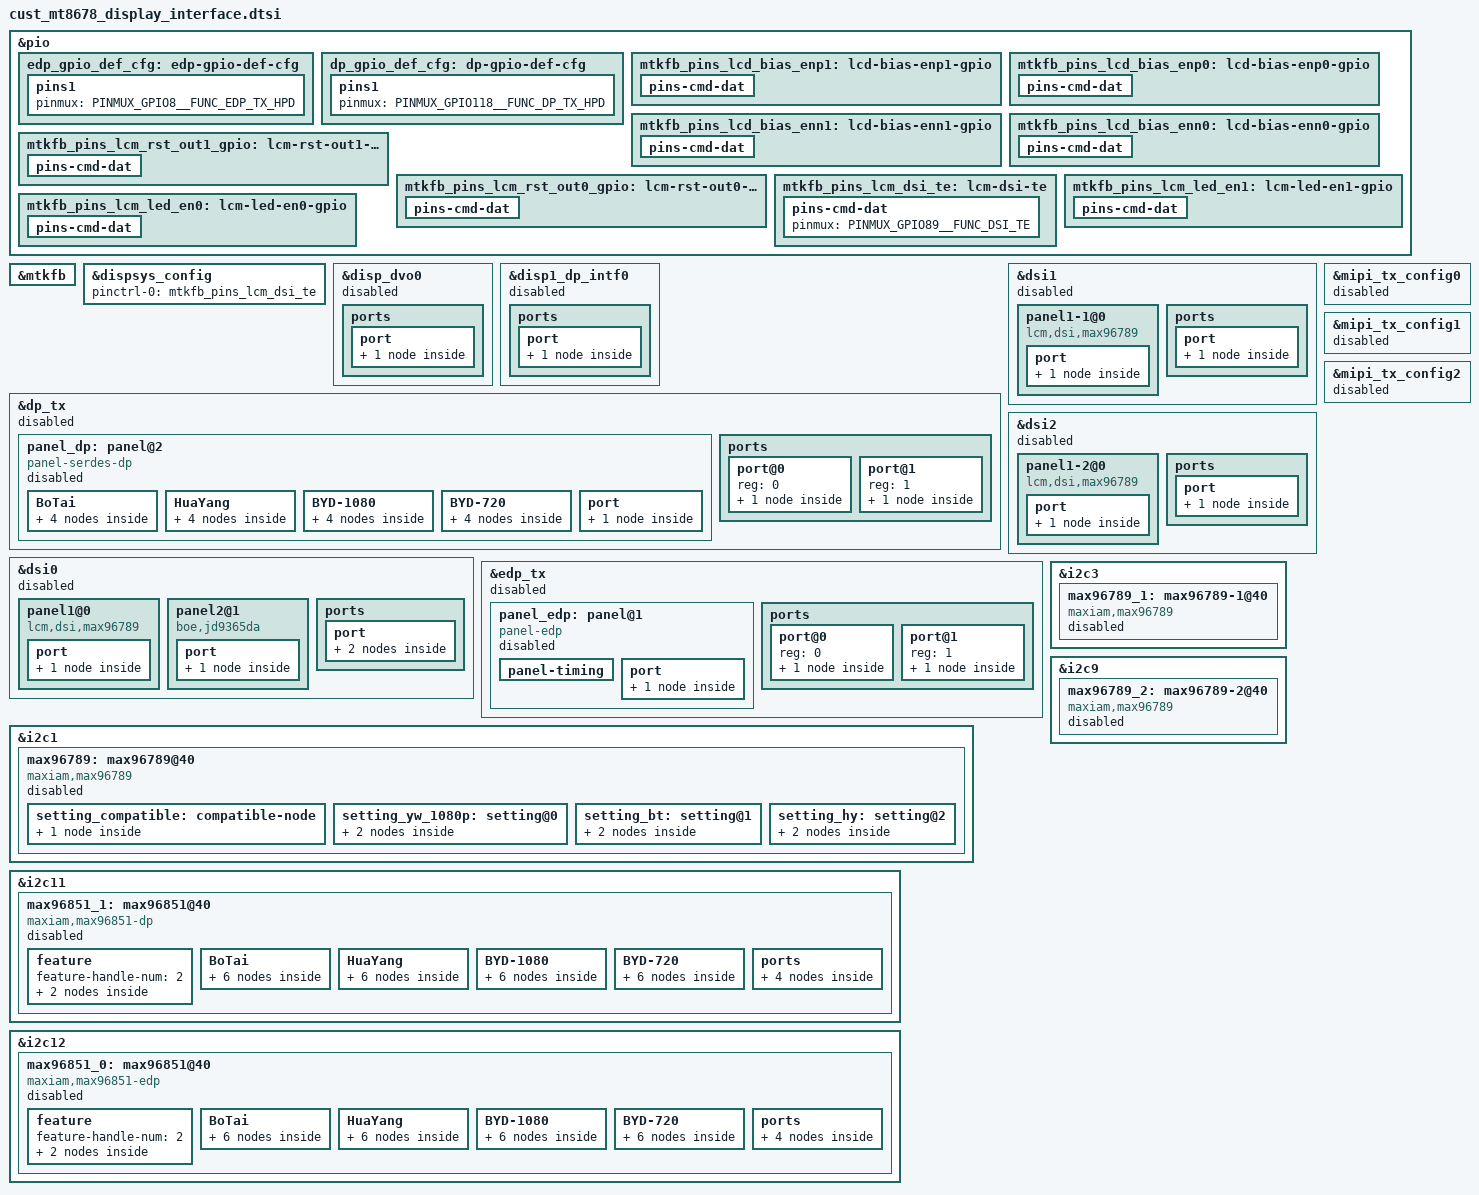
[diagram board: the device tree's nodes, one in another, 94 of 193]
// SPDX-License-Identifier: (GPL-2.0 OR MIT)
/*
 * Copyright (C) 2022 MediaTek Inc.
 */

&pio {
	edp_gpio_def_cfg: edp-gpio-def-cfg{
		pins1 {
			pinmux = <PINMUX_GPIO8__FUNC_EDP_TX_HPD>;
		};
	};

	dp_gpio_def_cfg: dp-gpio-def-cfg {
		pins1 {
			pinmux = <PINMUX_GPIO118__FUNC_DP_TX_HPD>;
		};
	};

	mtkfb_pins_lcd_bias_enp1: lcd-bias-enp1-gpio {
		pins-cmd-dat {
			pinmux = <PINMUX_GPIO103__FUNC_GPIO103>;
			slew-rate = <1>;
			output-high;
		};
	};

	mtkfb_pins_lcd_bias_enp0: lcd-bias-enp0-gpio {
		pins-cmd-dat {
			pinmux = <PINMUX_GPIO103__FUNC_GPIO103>;
			slew-rate = <1>;
			output-low;
		};
	};

	mtkfb_pins_lcd_bias_enn1: lcd-bias-enn1-gpio {
		pins-cmd-dat {
			pinmux = <PINMUX_GPIO103__FUNC_GPIO103>;
			slew-rate = <1>;
			output-high;
		};
	};

	mtkfb_pins_lcd_bias_enn0: lcd-bias-enn0-gpio {
		pins-cmd-dat {
			pinmux = <PINMUX_GPIO103__FUNC_GPIO103>;
			slew-rate = <1>;
			output-low;
		};
	};

	mtkfb_pins_lcm_rst_out1_gpio: lcm-rst-out1-gpio {
		pins-cmd-dat {
			pinmux = <PINMUX_GPIO90__FUNC_GPIO90>;
			slew-rate = <1>;
			output-high;
		};
	};

	mtkfb_pins_lcm_rst_out0_gpio: lcm-rst-out0-gpio {
		pins-cmd-dat {
			pinmux = <PINMUX_GPIO90__FUNC_GPIO90>;
			slew-rate = <1>;
			output-low;
		};
	};
	mtkfb_pins_lcm_dsi_te: lcm-dsi-te {
		pins-cmd-dat {
			pinmux = <PINMUX_GPIO89__FUNC_DSI_TE>;
		};
	};

	mtkfb_pins_lcm_led_en1: lcm-led-en1-gpio {
		pins-cmd-dat {
			pinmux = <PINMUX_GPIO103__FUNC_GPIO103>;
			slew-rate = <1>;
			output-high;
		};
	};

	mtkfb_pins_lcm_led_en0: lcm-led-en0-gpio {
		pins-cmd-dat {
			pinmux = <PINMUX_GPIO79__FUNC_GPIO79>;
			slew-rate = <1>;
			output-low;
		};
	};
};

&mtkfb {
	pinctrl-names = "lcd_bias_enp1_gpio", "lcd_bias_enp0_gpio",
		"lcd_bias_enn1_gpio", "lcd_bias_enn0_gpio",
		"lcm_rst_out1_gpio", "lcm_rst_out0_gpio",
		"mode_te_te", "lcm_led_en1_gpio", "lcm_led_en0_gpio";
	pinctrl-0 = <&mtkfb_pins_lcd_bias_enp1>;
	pinctrl-1 = <&mtkfb_pins_lcd_bias_enp0>;
	pinctrl-2 = <&mtkfb_pins_lcd_bias_enn1>;
	pinctrl-3 = <&mtkfb_pins_lcd_bias_enn0>;
	pinctrl-4 = <&mtkfb_pins_lcm_rst_out1_gpio>;
	pinctrl-5 = <&mtkfb_pins_lcm_rst_out0_gpio>;
	pinctrl-6 = <&mtkfb_pins_lcm_dsi_te>;
	pinctrl-7 = <&mtkfb_pins_lcm_led_en1>;
	pinctrl-8 = <&mtkfb_pins_lcm_led_en0>;

	status = "okay";
};

&dispsys_config {
	pinctrl-names = "mode_te_te";
	pinctrl-0 = <&mtkfb_pins_lcm_dsi_te>;
	status = "okay";
};

&disp_dvo0 {
	status = "disabled";
	ports {
		port {
			disp_dvo0_out: endpoint {
				remote-endpoint = <&edptx_in>;
			};
		};
	};
};

&disp1_dp_intf0 {
	status = "disabled";
	ports {
		port {
			disp1_dp_intf0_out: endpoint {
				remote-endpoint = <&dptx_in>;
			};
		};
	};
};

&dp_tx {
	pinctrl-names = "default";
	pinctrl-0 = <&dp_gpio_def_cfg>;
	status = "disabled";
	direct-dp;

	panel_dp: panel@2 {
		compatible = "panel-serdes-dp";
		status = "disabled";
	};

	ports {
		port@0 {
			reg = <0>;
			dptx_in: endpoint {
				remote-endpoint = <&disp1_dp_intf0_out>;
			};
		};
		port@1 {
			reg = <1>;
			dptx_out: endpoint {
				remote-endpoint = <&panel_dp_in>;
			};
		};
	};
};

&dsi0 {
	status = "disabled";
	#address-cells = <1>;
	#size-cells = <0>;
	panel1@0 {
		compatible = "lcm,dsi,max96789";
		reg = <0>;

		ser = <&max96789>;
		port {
			panel_in1: endpoint {
				remote-endpoint = <&dsi_out>;
			};
		};
	};
	panel2@1 {
		compatible = "boe,jd9365da";
		reg = <1>;
		power-gpios = <&pio 79 0>;
		reset-gpios = <&pio 90 0>;
		pinctrl-names = "default";
		port {
			panel_in2: endpoint {
				remote-endpoint = <&dsi_out2>;
			};
		};
	};
	ports {
		port {
			dsi_out: endpoint@0 {
				remote-endpoint = <&panel_in1>;
			};

			dsi_out2: endpoint@1 {
				remote-endpoint = <&panel_in2>;
			};
		};
	};
};

&dsi1 {
	status = "disabled";
	#address-cells = <1>;
	#size-cells = <0>;
	panel1-1@0 {
		compatible = "lcm,dsi,max96789";
		reg = <0>;

		ser = <&max96789_1>;
		port {
			panel1_in: endpoint {
				remote-endpoint = <&dsi1_out>;
			};
		};
	};
	ports {
		port {
			dsi1_out: endpoint@0 {
				remote-endpoint = <&panel1_in>;
			};
		};
	};
};

&dsi2 {
	status = "disabled";
	#address-cells = <1>;
	#size-cells = <0>;
	panel1-2@0 {
		compatible = "lcm,dsi,max96789";
		reg = <0>;

		ser = <&max96789_2>;
		port {
			panel2_in: endpoint {
				remote-endpoint = <&dsi2_out>;
			};
		};
	};
	ports {
		port {
			dsi2_out: endpoint@0 {
				remote-endpoint = <&panel2_in>;
			};
		};
	};
};

&edp_tx {
	status = "disabled";
	max-lane-count = <4>;
	max-linkrate-mhz = <8100>;
	use-hpd;
	use-edid;
	external-monitor;

	panel_edp: panel@1 {
		compatible = "panel-edp";
		status = "disabled";
	};

	ports {
		port@0 {
			reg = <0>;
			edptx_in: endpoint {
				remote-endpoint = <&disp_dvo0_out>;
			};
		};
		port@1 {
			reg = <1>;
			edptx_out: endpoint {
				remote-endpoint = <&panel_edp_in>;
			};
		};
	};
};

&i2c1 {
	status = "okay";
	max96789: max96789@40 {
		compatible = "maxiam,max96789";
		status = "disabled";
		reg = <0x40>;
		reset-gpios = <&pio 37 0>;
		pinctrl-names = "default";
		setting = <&setting_compatible>;
		inited-in-lk = <1>;
	};
};

&i2c3 {
	status = "okay";
	max96789_1: max96789-1@40 {
		compatible = "maxiam,max96789";
		status = "disabled";
		reg = <0x40>;
		reset-gpios = <&pio 38 0>;
		pinctrl-names = "default";
		setting = <&setting_compatible>;
	};
};

&i2c9 {
	status = "okay";
	max96789_2: max96789-2@40 {
		compatible = "maxiam,max96789";
		status = "disabled";
		reg = <0x40>;
		reset-gpios = <&pio 24 0>;
		pinctrl-names = "default";
		setting = <&setting_compatible>;
	};
};

&i2c11 {
	status = "okay";
	max96851_1: max96851@40 {
		status = "disabled";
		compatible = "maxiam,max96851-dp";
		reg = <0x40>;
		pinctrl-names = "default";
		reset-gpios = <&pio 70 0>;

		panel-name = "BYD-1080";
		ser-super-frame = <0>;
		ser-dual-link = <0>;
		ser-dp-mst = <0>;
		support-touch = <1>;

		feature{
			feature-handle-num = <2>;
			feature-handle0{
				check-cmd = <0x01 0x01 0x1a 0xb 0x83 0x50 0x00 0x01 0x00 0x00 0x00 0x00 0x00 0x00 0xd4>;
				verify-cmd = <0x01 0x00 0x1a 0x02 0xff 0xff>;
				feature-setting = "HuaYang";
			};
			feature-handle1{
				check-cmd = <0x01 0x00 0x1a 0xb 0x83 0x50 0x00 0x01 0x00 0x00 0x00 0x00 0x00 0x00 0xd4>;
				verify-cmd = <0x01 0x00 0x1a 0x02 0xf0 0x10>;
				feature-setting = "BoTai";
			};
		};

		BoTai{
			max96851-signal-settting{
				ser-init-cmd = <
					0 0x0100 0x61 0
					0 0x7000 0x00 0
					0 0x7019 0x00 0
					0 0x70a0 0x04 0
					0 0x7074 0x14 0
					0 0x7070 0x04 0
					0 0x7000 0x01 0x200
				>;
				des-i2c-addr = <0x4c>;
				des-init-cmd = <
					1 0x01ce 0x5e 2
				>;
				touch-init-cmd =<
				>;
				bl-i2c-addr = <0x1a>;
				bl-on-cmd = <
					0x83 0x50 0x00 0x01 0x00 0x00 0x00 0x00 0x00 0x00 0xd4
				>;
				bl-off-cmd = <
					0x83 0x00 0x00 0x02 0x00 0x00 0x00 0x00 0x00 0x00 0x85
				>;
			};

			max96851-superframe-setting{
				asymmetric-multi-view = <0>;
				symmetric-multi-view-setting{
					des-i2c-addr = <0x4c>;
					serdes-init-linka-cmd = <
						0 0x0028 0x88 0
						0 0x0032 0x08 200
						1 0x0000 0x94 0
					>;
					des-linka-i2c-addr = <0x4a>;
					des-linka-bl-i2c-addr = <0x1b>;
					des-linka-init-cmd = <
						2 0x01ce 0x5e 0
						2 0x01ea 0x05 0
						2 0x0042 0x36 0
						2 0x0043 0x34 0
					>;
					des-linkb-i2c-addr = <0x48>;
					des-linkb-bl-i2c-addr = <0x1c>;
					serdes-init-linkb-cmd = <
						0 0x0028 0x08 0
						0 0x0032 0x88 200
						1 0x0000 0x90 0
					>;
					des-linkb-init-cmd = <
						3 0x01ce 0x5e 0
						3 0x01ea 0x05 0
						3 0x0050 0x01 0
						3 0x0042 0x38 0
						3 0x0043 0x34 0
					>;
					ser-superframe-init-cmd = <
						0 0x0028 0x88 0
						0 0x0032 0x88 0
						0 0x0029 0x02 0
						0 0x0033 0x02 0
						0 0x05ce 0x37 0
						0 0x04d1 0xf8 0
						0 0x05d1 0xf8 0
						0 0x04cf 0xbf 0
						0 0x05cf 0xbf 0
						0 0x04d1 0xfc 0
						0 0x05d1 0xfc 0
						0 0x04ce 0x0f 0
						0 0x05ce 0x07 0
						0 0x0110 0x63 0
						0 0x04c0 0x80 0
						0 0x04c1 0x6b 0
						0 0x04c2 0x23 0
						0 0x04c3 0xc8 0
						0 0x04c4 0x08 0
						0 0x04c5 0x07 0
						0 0x04c6 0x00 0
						0 0x04c7 0x00 0
						0 0x04c8 0x80 0
						0 0x04c9 0x07 0
						0 0x04ca 0x38 0
						0 0x04cb 0x04 0
						0 0x05c0 0x80 0
						0 0x05c1 0x6b 0
						0 0x05c2 0x23 0
						0 0x05c3 0xc8 0
						0 0x05c4 0x08 0
						0 0x05c5 0x07 0
						0 0x05c6 0x80 0
						0 0x05c7 0x07 0
						0 0x05c8 0x00 0
						0 0x05c9 0x0f 0
						0 0x05ca 0x38 0
						0 0x05cb 0x04 0
						0 0x04d8 0x00 0
						0 0x04d9 0x0a 0
						0 0x04da 0x23 0
						0 0x04db 0x40 0
						0 0x04dc 0x10 0
						0 0x04dd 0x00 0
						0 0x04de 0x40 0
						0 0x04df 0x51 0
						0 0x04e0 0x00 0
						0 0x04e1 0x00 0
						0 0x04e2 0x00 0
						0 0x04e3 0x00 0
						0 0x04e4 0x28 0
						0 0x04e5 0x00 0
						0 0x04e6 0xf8 0
						0 0x04e7 0x07 0
						0 0x04e8 0x5c 0
						0 0x04e9 0x04 0
						0 0x04ea 0x00 0
						0 0x04eb 0x00 0
						0 0x04ec 0x00 0
						0 0x04ed 0x78 0
						0 0x04ee 0x00 0
						0 0x04ef 0x00 0
						0 0x04f0 0x80 0
						0 0x04f1 0x07 0
						0 0x04f2 0xa0 0
						0 0x04f3 0x00 0
						0 0x04f4 0x38 0
						0 0x04f5 0x04 0
						0 0x04f6 0x08 0
						0 0x04f7 0x24 0
						0 0x04f8 0x01 0
						0 0x05d8 0x00 0
						0 0x05d9 0x0a 0
						0 0x05da 0x23 0
						0 0x05db 0x40 0
						0 0x05dc 0x10 0
						0 0x05dd 0x00 0
						0 0x05de 0x40 0
						0 0x05df 0x51 0
						0 0x05e0 0x00 0
						0 0x05e1 0x00 0
						0 0x05e2 0x00 0
						0 0x05e3 0x00 0
						0 0x05e4 0x28 0
						0 0x05e5 0x00 0
						0 0x05e6 0xf8 0
						0 0x05e7 0x07 0
						0 0x05e8 0x5c 0
						0 0x05e9 0x04 0
						0 0x05ea 0x00 0
						0 0x05eb 0x00 0
						0 0x05ec 0x00 0
						0 0x05ed 0x78 0
						0 0x05ee 0x00 0
						0 0x05ef 0x00 0
						0 0x05f0 0x80 0
						0 0x05f1 0x07 0
						0 0x05f2 0xa0 0
						0 0x05f3 0x00 0
						0 0x05f4 0x38 0
						0 0x05f5 0x04 0
						0 0x05f6 0x08 0
						0 0x05f7 0x24 0
						0 0x05f8 0x01 0
						0 0x05cd 0x14 0
						0 0x6420 0x10 0
						0 0x7019 0x00 0
						0 0x7a14 0x00 0
						0 0x7000 0x00 0
						0 0x7054 0x01 1000
						0 0x7074 0x14 0
						0 0x7070 0x04 0
						0 0x04d0 0x0a 0
						0 0x05d0 0x0a 0
						0 0x6064 0x0f 0
						0 0x6065 0x0f 0
						0 0x6164 0x0f 0
						0 0x6165 0x0f 0
						0 0x6264 0x0f 0
						0 0x6265 0x0f 0
						0 0x6364 0x0f 0
						0 0x6365 0x0f 0
						0 0x7000 0x01 1000
						0 0x7a18 0x05 0
						0 0x7a28 0xff 0
						0 0x7a2a 0xff 0
						0 0x7a24 0xff 0
						0 0x7a27 0x0f 0
						0 0x7a14 0x01 0
						0 0x6421 0x01 0
						0 0x6420 0x11 100
						0 0x6420 0x10 100
						0 0x6420 0x11 0
					>;
					serdes-superframe-touch-init-cmd = <
					>;
					bl-i2c-addr = <0x1a>;
					bl-on-cmd = <
						0x83 0x50 0x00 0x01 0x00 0x00 0x00 0x00 0x00 0x00 0xd4
					>;
					bl-off-cmd = <
						0x83 0x00 0x00 0x02 0x00 0x00 0x00 0x00 0x00 0x00 0x85
					>;
				};
				asymmetric-multi-view-setting{
				};
			};

			max96851-dual-link-setting{
			};

			max96851-dp-mst-setting{
			};
		};

		HuaYang{
			max96851-signal-settting{
				ser-init-cmd = <
					0 0x0100 0x61 0
					0 0x7000 0x00 0
					0 0x7019 0x00 0
					0 0x70a0 0x04 0
					0 0x7074 0x14 0
					0 0x7070 0x04 0
					0 0x7000 0x01 0x200
				>;
				des-i2c-addr = <0x4c>;
				des-init-cmd = <
					1 0x01ce 0x4e 2
				>;
				touch-init-cmd =<
				>;
				bl-i2c-addr = <0x1a>;
				bl-on-cmd = <
					0x83 0x50 0x00 0x01 0x00 0x00 0x00 0x00 0x00 0x00 0xd4
				>;
				bl-off-cmd = <
					0x83 0x00 0x00 0x02 0x00 0x00 0x00 0x00 0x00 0x00 0x85
				>;
			};

			max96851-superframe-setting{
				asymmetric-multi-view = <0>;
				symmetric-multi-view-setting{
					des-i2c-addr = <0x4c>;
					serdes-init-linka-cmd = <
						0 0x0028 0x88 0
						0 0x0032 0x08 200
						1 0x0000 0x94 0
					>;
					des-linka-i2c-addr = <0x4a>;
					des-linka-bl-i2c-addr = <0x1b>;
					des-linka-init-cmd = <
						2 0x01ce 0x4e 0
						2 0x01ea 0x05 0
						2 0x0042 0x36 0
						2 0x0043 0x34 0
					>;
					des-linkb-i2c-addr = <0x48>;
					des-linkb-bl-i2c-addr = <0x1c>;
					serdes-init-linkb-cmd = <
						0 0x0028 0x08 0
						0 0x0032 0x88 200
						1 0x0000 0x90 0
					>;
					des-linkb-init-cmd = <
						3 0x01ce 0x4e 0
						3 0x01ea 0x05 0
						3 0x0050 0x01 0
						3 0x0042 0x38 0
						3 0x0043 0x34 0
					>;
					ser-superframe-init-cmd = <
						0 0x0028 0x88 0
						0 0x0032 0x88 0
						0 0x0029 0x02 0
						0 0x0033 0x02 0
						0 0x05ce 0x37 0
						0 0x04d1 0xf8 0
						0 0x05d1 0xf8 0
						0 0x04cf 0xbf 0
						0 0x05cf 0xbf 0
						0 0x04d1 0xfc 0
						0 0x05d1 0xfc 0
						0 0x04ce 0x0f 0
						0 0x05ce 0x07 0
						0 0x0110 0x63 0
						0 0x04c0 0x80 0
						0 0x04c1 0x6b 0
						0 0x04c2 0x23 0
						0 0x04c3 0xc8 0
						0 0x04c4 0x08 0
						0 0x04c5 0x07 0
						0 0x04c6 0x00 0
						0 0x04c7 0x00 0
						0 0x04c8 0x80 0
						0 0x04c9 0x07 0
						0 0x04ca 0x38 0
						0 0x04cb 0x04 0
						0 0x05c0 0x80 0
						0 0x05c1 0x6b 0
						0 0x05c2 0x23 0
						0 0x05c3 0xc8 0
						0 0x05c4 0x08 0
						0 0x05c5 0x07 0
						0 0x05c6 0x80 0
						0 0x05c7 0x07 0
						0 0x05c8 0x00 0
						0 0x05c9 0x0f 0
						0 0x05ca 0x38 0
						0 0x05cb 0x04 0
						0 0x04d8 0x00 0
						0 0x04d9 0x0a 0
						0 0x04da 0x23 0
						0 0x04db 0x40 0
						0 0x04dc 0x10 0
						0 0x04dd 0x00 0
						0 0x04de 0x40 0
						0 0x04df 0x51 0
						0 0x04e0 0x00 0
						0 0x04e1 0x00 0
						0 0x04e2 0x00 0
						0 0x04e3 0x00 0
						0 0x04e4 0x28 0
						0 0x04e5 0x00 0
						0 0x04e6 0xf8 0
						0 0x04e7 0x07 0
						0 0x04e8 0x5c 0
						0 0x04e9 0x04 0
						0 0x04ea 0x00 0
						0 0x04eb 0x00 0
						0 0x04ec 0x00 0
						0 0x04ed 0x78 0
						0 0x04ee 0x00 0
						0 0x04ef 0x00 0
						0 0x04f0 0x80 0
						0 0x04f1 0x07 0
						0 0x04f2 0xa0 0
						0 0x04f3 0x00 0
						0 0x04f4 0x38 0
						0 0x04f5 0x04 0
						0 0x04f6 0x08 0
						0 0x04f7 0x24 0
						0 0x04f8 0x01 0
						0 0x05d8 0x00 0
						0 0x05d9 0x0a 0
						0 0x05da 0x23 0
						0 0x05db 0x40 0
						0 0x05dc 0x10 0
						0 0x05dd 0x00 0
						0 0x05de 0x40 0
						0 0x05df 0x51 0
						0 0x05e0 0x00 0
						0 0x05e1 0x00 0
						0 0x05e2 0x00 0
						0 0x05e3 0x00 0
						0 0x05e4 0x28 0
						0 0x05e5 0x00 0
						0 0x05e6 0xf8 0
						0 0x05e7 0x07 0
						0 0x05e8 0x5c 0
						0 0x05e9 0x04 0
						0 0x05ea 0x00 0
						0 0x05eb 0x00 0
						0 0x05ec 0x00 0
						0 0x05ed 0x78 0
						0 0x05ee 0x00 0
						0 0x05ef 0x00 0
						0 0x05f0 0x80 0
						0 0x05f1 0x07 0
						0 0x05f2 0xa0 0
						0 0x05f3 0x00 0
						0 0x05f4 0x38 0
						0 0x05f5 0x04 0
						0 0x05f6 0x08 0
						0 0x05f7 0x24 0
						0 0x05f8 0x01 0
						0 0x05cd 0x14 0
						0 0x6420 0x10 0
						0 0x7019 0x00 0
						0 0x7a14 0x00 0
						0 0x7000 0x00 0
						0 0x7054 0x01 1000
						0 0x7074 0x14 0
						0 0x7070 0x04 0
						0 0x04d0 0x0a 0
						0 0x05d0 0x0a 0
						0 0x6064 0x0f 0
						0 0x6065 0x0f 0
						0 0x6164 0x0f 0
						0 0x6165 0x0f 0
						0 0x6264 0x0f 0
						0 0x6265 0x0f 0
						0 0x6364 0x0f 0
						0 0x6365 0x0f 0
						0 0x7000 0x01 1000
						0 0x7a18 0x05 0
						0 0x7a28 0xff 0
						0 0x7a2a 0xff 0
						0 0x7a24 0xff 0
						0 0x7a27 0x0f 0
						0 0x7a14 0x01 0
						0 0x6421 0x01 0
						0 0x6420 0x11 100
						0 0x6420 0x10 100
						0 0x6420 0x11 0
					>;
					serdes-superframe-touch-init-cmd = <
					>;
					bl-i2c-addr = <0x1a>;
					bl-on-cmd = <
						0x83 0x50 0x00 0x01 0x00 0x00 0x00 0x00 0x00 0x00 0xd4
					>;
					bl-off-cmd = <
						0x83 0x00 0x00 0x02 0x00 0x00 0x00 0x00 0x00 0x00 0x85
					>;
				};
				asymmetric-multi-view-setting{
				};
			};

			max96851-dual-link-setting{
			};

			max96851-dp-mst-setting{
			};
		};

		BYD-1080{
			max96851-signal-settting{
				ser-init-cmd = <
					0 0x0100 0x61 0
					0 0x7000 0x00 0
					0 0x7019 0x00 0
					0 0x70a0 0x04 0
					0 0x7074 0x14 0
					0 0x7070 0x04 0
					0 0x7000 0x01 200
				>;
				des-i2c-addr = <0x4a>;
				des-init-cmd = <
					1 0x0215 0x10 0
					1 0x0227 0x10 0
					1 0x020f 0x10 0
					1 0x021b 0x10 0
					1 0x020c 0x10 0
					1 0x0209 0x10 0
					1 0x0212 0x10 0
					1 0x005b 0x31 0
					1 0x0063 0x31 0
					1 0x006b 0x31 0
					1 0x0073 0x31 0
					1 0x007b 0x31 0
					1 0x008b 0x31 0
					1 0x00a3 0x31 0
					1 0x00ab 0x31 0
					1 0x0140 0x20 0
					1 0x0002 0x43 0
					1 0x01d2 0x22 0
					1 0x01d4 0x44 0
					1 0x0010 0x11 0
					1 0x01ce 0x5e 0
					1 0x01c8 0x38 0
					1 0x01c9 0x39 0
					1 0x01ca 0x3a 0
					1 0x0002 0x03 0
					1 0x0d00 0xf4 0
					1 0x0002 0x43 0
					1 0x0d00 0xf5 0
					1 0x01c8 0x18 0
					1 0x01c9 0x19 0
					1 0x01ca 0x1a 0
				>;
				touch-init-cmd =<
					1 0x0206 0x03 0
					1 0x0207 0xab 0
					1 0x0208 0x4b 0
					0 0x0258 0x00 0
					0 0x0259 0xab 0
					0 0x025a 0x4b 0
					0 0x025b 0x22 0
				>;
				bl-i2c-addr = <0x1a>;
				bl-on-cmd = <
					0x83 0x50 0x00 0x01 0x00 0x00 0x00 0x00 0x00 0x00 0x00
				>;
				bl-off-cmd = <
					0x83 0x00 0x00 0x02 0x00 0x00 0x00 0x00 0x00 0x00 0x85
				>;
			};

			max96851-superframe-setting{
				asymmetric-multi-view = <0>;
				symmetric-multi-view-setting{
					des-i2c-addr = <0x4a>;
					serdes-init-linka-cmd = <
					>;
					des-linka-i2c-addr = <0x4a>;
					des-linka-bl-i2c-addr = <0x1b>;
					des-linka-init-cmd = <
					>;
					des-linkb-i2c-addr = <0x48>;
					des-linkb-bl-i2c-addr = <0x1c>;
					serdes-init-linkb-cmd = <
					>;
					des-linkb-init-cmd = <
					>;
					ser-superframe-init-cmd = <
					>;
					serdes-superframe-touch-init-cmd = <
					>;
					bl-i2c-addr = <0x1a>;
					bl-on-cmd = <
						0x83 0x50 0x00 0x01 0x00 0x00 0x00 0x00 0x00 0x00 0x00
					>;
					bl-off-cmd = <
						0x83 0x00 0x00 0x02 0x00 0x00 0x00 0x00 0x00 0x00 0x85
					>;
				};
				asymmetric-multi-view-setting{
				};
			};

			max96851-dual-link-setting{
			};

			max96851-dp-mst-setting{
			};
		};

		BYD-720{
			max96851-signal-settting{
				ser-init-cmd = <
				>;
				des-i2c-addr = <0x4a>;
				des-init-cmd = <
				>;
				touch-init-cmd =<
				>;
				bl-i2c-addr = <0x1a>;
				bl-on-cmd = <
					0x83 0x50 0x00 0x01 0x00 0x00 0x00 0x00 0x00 0x00 0xd4
				>;
				bl-off-cmd = <
					0x83 0x00 0x00 0x02 0x00 0x00 0x00 0x00 0x00 0x00 0x85
				>;
			};
			max96851-superframe-setting{
				asymmetric-multi-view = <0>;
				symmetric-multi-view-setting{
					des-i2c-addr = <0x4c>;
					serdes-init-linka-cmd = <
					>;
					des-linka-i2c-addr = <0x4a>;
					des-linka-bl-i2c-addr = <0x1b>;
					des-linka-init-cmd = <
					>;
					des-linkb-i2c-addr = <0x48>;
					des-linkb-bl-i2c-addr = <0x1c>;
					serdes-init-linkb-cmd = <
					>;
					des-linkb-init-cmd = <
					>;
					ser-superframe-init-cmd = <
					>;
					serdes-superframe-touch-init-cmd = <
					>;
					bl-i2c-addr = <0x1a>;
					bl-on-cmd = <
						0x83 0x50 0x00 0x01 0x00 0x00 0x00 0x00 0x00 0x00 0xd4
					>;
					bl-off-cmd = <
						0x83 0x00 0x00 0x02 0x00 0x00 0x00 0x00 0x00 0x00 0x85
					>;
				};
				asymmetric-multi-view-setting{
				};
			};
			max96851-dual-link-setting{
			};
			max96851-dp-mst-setting{
			};
		};

		ports {
			port@0 {
				reg = <0>;
				serdes_dp_in: endpoint {
					remote-endpoint = <&dptx_out>;
				};
			};

			port@1 {
				reg = <1>;
				serdes_dp_out: endpoint {
					remote-endpoint = <&panel_dp_in>;
				};
			};
		};
	};
};

&i2c12 {
	status = "okay";
	max96851_0: max96851@40 {
		status = "disabled";
		compatible = "maxiam,max96851-edp";
		reg = <0x40>;
		pinctrl-names = "default";
		reset-gpios = <&pio 73 0>;

		panel-name = "BYD-720";
		ser-super-frame = <0>;
		ser-dual-link = <0>;
		ser-dp-mst = <0>;
		support-touch = <1>;

		feature{
			feature-handle-num = <2>;
			feature-handle0{
				check-cmd = <0x01 0x01 0x1a 0xb 0x83 0x50 0x00 0x01 0x00 0x00 0x00 0x00 0x00 0x00 0xd4>;
				verify-cmd = <0x01 0x00 0x1a 0x02 0xff 0xff>;
				feature-setting = "HuaYang";
			};
			feature-handle1{
				check-cmd = <0x01 0x00 0x1a 0xb 0x83 0x50 0x00 0x01 0x00 0x00 0x00 0x00 0x00 0x00 0xd4>;
				verify-cmd = <0x01 0x00 0x1a 0x02 0xf0 0x10>;
				feature-setting = "BoTai";
			};
		};

		BoTai{
			max96851-signal-settting{
				ser-init-cmd = <
					0 0x0100 0x61 0
					0 0x7000 0x00 0
					0 0x7019 0x00 0
					0 0x70a0 0x04 0
					0 0x7074 0x14 0
					0 0x7070 0x04 0
					0 0x7000 0x01 0x200
				>;
				des-i2c-addr = <0x4c>;
				des-init-cmd = <
					1 0x01ce 0x5e 2
				>;
				touch-init-cmd =<
				>;
				bl-i2c-addr = <0x1a>;
				bl-on-cmd = <
					0x83 0x50 0x00 0x01 0x00 0x00 0x00 0x00 0x00 0x00 0xd4
				>;
				bl-off-cmd = <
					0x83 0x00 0x00 0x02 0x00 0x00 0x00 0x00 0x00 0x00 0x85
				>;
			};

			max96851-superframe-setting{
				asymmetric-multi-view = <0>;
				symmetric-multi-view-setting{
					des-i2c-addr = <0x4c>;
					serdes-init-linka-cmd = <
						0 0x0028 0x88 0
						0 0x0032 0x08 200
						1 0x0000 0x94 0
					>;
					des-linka-i2c-addr = <0x4a>;
					des-linka-bl-i2c-addr = <0x1b>;
					des-linka-init-cmd = <
						2 0x01ce 0x5e 0
						2 0x01ea 0x05 0
						2 0x0042 0x36 0
						2 0x0043 0x34 0
					>;
					des-linkb-i2c-addr = <0x48>;
					des-linkb-bl-i2c-addr = <0x1c>;
					serdes-init-linkb-cmd = <
						0 0x0028 0x08 0
						0 0x0032 0x88 200
						1 0x0000 0x90 0
					>;
					des-linkb-init-cmd = <
						3 0x01ce 0x5e 0
						3 0x01ea 0x05 0
						3 0x0050 0x01 0
						3 0x0042 0x38 0
						3 0x0043 0x34 0
					>;
					ser-superframe-init-cmd = <
						0 0x0028 0x88 0
						0 0x0032 0x88 0
						0 0x0029 0x02 0
						0 0x0033 0x02 0
						0 0x05ce 0x37 0
						0 0x04d1 0xf8 0
						0 0x05d1 0xf8 0
						0 0x04cf 0xbf 0
						0 0x05cf 0xbf 0
						0 0x04d1 0xfc 0
						0 0x05d1 0xfc 0
						0 0x04ce 0x0f 0
						0 0x05ce 0x07 0
						0 0x0110 0x63 0
						0 0x04c0 0x80 0
						0 0x04c1 0x6b 0
						0 0x04c2 0x23 0
						0 0x04c3 0xc8 0
						0 0x04c4 0x08 0
						0 0x04c5 0x07 0
						0 0x04c6 0x00 0
						0 0x04c7 0x00 0
						0 0x04c8 0x80 0
						0 0x04c9 0x07 0
						0 0x04ca 0x38 0
						0 0x04cb 0x04 0
						0 0x05c0 0x80 0
						0 0x05c1 0x6b 0
						0 0x05c2 0x23 0
						0 0x05c3 0xc8 0
						0 0x05c4 0x08 0
						0 0x05c5 0x07 0
						0 0x05c6 0x80 0
						0 0x05c7 0x07 0
						0 0x05c8 0x00 0
						0 0x05c9 0x0f 0
						0 0x05ca 0x38 0
						0 0x05cb 0x04 0
						0 0x04d8 0x00 0
						0 0x04d9 0x0a 0
						0 0x04da 0x23 0
						0 0x04db 0x40 0
						0 0x04dc 0x10 0
						0 0x04dd 0x00 0
						0 0x04de 0x40 0
						0 0x04df 0x51 0
						0 0x04e0 0x00 0
						0 0x04e1 0x00 0
						0 0x04e2 0x00 0
						0 0x04e3 0x00 0
						0 0x04e4 0x28 0
						0 0x04e5 0x00 0
						0 0x04e6 0xf8 0
						0 0x04e7 0x07 0
						0 0x04e8 0x5c 0
						0 0x04e9 0x04 0
						0 0x04ea 0x00 0
						0 0x04eb 0x00 0
						0 0x04ec 0x00 0
						0 0x04ed 0x78 0
						0 0x04ee 0x00 0
						0 0x04ef 0x00 0
						0 0x04f0 0x80 0
						0 0x04f1 0x07 0
						0 0x04f2 0xa0 0
						0 0x04f3 0x00 0
						0 0x04f4 0x38 0
						0 0x04f5 0x04 0
						0 0x04f6 0x08 0
						0 0x04f7 0x24 0
						0 0x04f8 0x01 0
						0 0x05d8 0x00 0
						0 0x05d9 0x0a 0
						0 0x05da 0x23 0
						0 0x05db 0x40 0
						0 0x05dc 0x10 0
						0 0x05dd 0x00 0
						0 0x05de 0x40 0
						0 0x05df 0x51 0
						0 0x05e0 0x00 0
						0 0x05e1 0x00 0
						0 0x05e2 0x00 0
						0 0x05e3 0x00 0
						0 0x05e4 0x28 0
						0 0x05e5 0x00 0
						0 0x05e6 0xf8 0
						0 0x05e7 0x07 0
						0 0x05e8 0x5c 0
						0 0x05e9 0x04 0
						0 0x05ea 0x00 0
						0 0x05eb 0x00 0
						0 0x05ec 0x00 0
						0 0x05ed 0x78 0
						0 0x05ee 0x00 0
						0 0x05ef 0x00 0
						0 0x05f0 0x80 0
						0 0x05f1 0x07 0
						0 0x05f2 0xa0 0
						0 0x05f3 0x00 0
						0 0x05f4 0x38 0
						0 0x05f5 0x04 0
						0 0x05f6 0x08 0
						0 0x05f7 0x24 0
						0 0x05f8 0x01 0
						0 0x05cd 0x14 0
						0 0x6420 0x10 0
						0 0x7019 0x00 0
						0 0x7a14 0x00 0
						0 0x7000 0x00 0
						0 0x7054 0x01 1000
						0 0x7074 0x14 0
						0 0x7070 0x04 0
						0 0x04d0 0x0a 0
						0 0x05d0 0x0a 0
						0 0x6064 0x0f 0
						0 0x6065 0x0f 0
						0 0x6164 0x0f 0
						0 0x6165 0x0f 0
						0 0x6264 0x0f 0
						0 0x6265 0x0f 0
						0 0x6364 0x0f 0
						0 0x6365 0x0f 0
						0 0x7000 0x01 1000
						0 0x7a18 0x05 0
						0 0x7a28 0xff 0
						0 0x7a2a 0xff 0
						0 0x7a24 0xff 0
						0 0x7a27 0x0f 0
						0 0x7a14 0x01 0
						0 0x6421 0x01 0
						0 0x6420 0x11 100
						0 0x6420 0x10 100
						0 0x6420 0x11 0
					>;
					serdes-superframe-touch-init-cmd = <
					>;
					bl-i2c-addr = <0x1a>;
					bl-on-cmd = <
						0x83 0x50 0x00 0x01 0x00 0x00 0x00 0x00 0x00 0x00 0xd4
					>;
					bl-off-cmd = <
						0x83 0x00 0x00 0x02 0x00 0x00 0x00 0x00 0x00 0x00 0x85
					>;
				};
				asymmetric-multi-view-setting{
				};
			};

			max96851-dual-link-setting{
			};

			max96851-dp-mst-setting{
			};
		};

		HuaYang{
			max96851-signal-settting{
				ser-init-cmd = <
					0 0x0100 0x61 0
					0 0x7000 0x00 0
					0 0x7019 0x00 0
					0 0x70a0 0x04 0
					0 0x7074 0x14 0
					0 0x7070 0x04 0
					0 0x7000 0x01 0x200
				>;
				des-i2c-addr = <0x4c>;
				des-init-cmd = <
					1 0x01ce 0x4e 2
				>;
				touch-init-cmd =<
				>;
				bl-i2c-addr = <0x1a>;
				bl-on-cmd = <
					0x83 0x50 0x00 0x01 0x00 0x00 0x00 0x00 0x00 0x00 0xd4
				>;
				bl-off-cmd = <
					0x83 0x00 0x00 0x02 0x00 0x00 0x00 0x00 0x00 0x00 0x85
				>;
			};

			max96851-superframe-setting{
				asymmetric-multi-view = <0>;
				symmetric-multi-view-setting{
					des-i2c-addr = <0x4c>;
					serdes-init-linka-cmd = <
						0 0x0028 0x88 0
						0 0x0032 0x08 200
						1 0x0000 0x94 0
					>;
					des-linka-i2c-addr = <0x4a>;
					des-linka-bl-i2c-addr = <0x1b>;
					des-linka-init-cmd = <
						2 0x01ce 0x4e 0
						2 0x01ea 0x05 0
						2 0x0042 0x36 0
						2 0x0043 0x34 0
					>;
					des-linkb-i2c-addr = <0x48>;
					des-linkb-bl-i2c-addr = <0x1c>;
					serdes-init-linkb-cmd = <
						0 0x0028 0x08 0
						0 0x0032 0x88 200
						1 0x0000 0x90 0
					>;
					des-linkb-init-cmd = <
						3 0x01ce 0x4e 0
						3 0x01ea 0x05 0
						3 0x0050 0x01 0
						3 0x0042 0x38 0
						3 0x0043 0x34 0
					>;
					ser-superframe-init-cmd = <
						0 0x0028 0x88 0
						0 0x0032 0x88 0
						0 0x0029 0x02 0
						0 0x0033 0x02 0
						0 0x05ce 0x37 0
						0 0x04d1 0xf8 0
						0 0x05d1 0xf8 0
						0 0x04cf 0xbf 0
						0 0x05cf 0xbf 0
						0 0x04d1 0xfc 0
						0 0x05d1 0xfc 0
						0 0x04ce 0x0f 0
						0 0x05ce 0x07 0
						0 0x0110 0x63 0
						0 0x04c0 0x80 0
						0 0x04c1 0x6b 0
						0 0x04c2 0x23 0
						0 0x04c3 0xc8 0
						0 0x04c4 0x08 0
						0 0x04c5 0x07 0
						0 0x04c6 0x00 0
						0 0x04c7 0x00 0
						0 0x04c8 0x80 0
						0 0x04c9 0x07 0
						0 0x04ca 0x38 0
						0 0x04cb 0x04 0
						0 0x05c0 0x80 0
						0 0x05c1 0x6b 0
						0 0x05c2 0x23 0
						0 0x05c3 0xc8 0
						0 0x05c4 0x08 0
						0 0x05c5 0x07 0
						0 0x05c6 0x80 0
						0 0x05c7 0x07 0
						0 0x05c8 0x00 0
						0 0x05c9 0x0f 0
						0 0x05ca 0x38 0
						0 0x05cb 0x04 0
						0 0x04d8 0x00 0
						0 0x04d9 0x0a 0
						0 0x04da 0x23 0
						0 0x04db 0x40 0
						0 0x04dc 0x10 0
						0 0x04dd 0x00 0
						0 0x04de 0x40 0
						0 0x04df 0x51 0
						0 0x04e0 0x00 0
						0 0x04e1 0x00 0
						0 0x04e2 0x00 0
						0 0x04e3 0x00 0
						0 0x04e4 0x28 0
						0 0x04e5 0x00 0
						0 0x04e6 0xf8 0
						0 0x04e7 0x07 0
						0 0x04e8 0x5c 0
						0 0x04e9 0x04 0
						0 0x04ea 0x00 0
						0 0x04eb 0x00 0
						0 0x04ec 0x00 0
						0 0x04ed 0x78 0
						0 0x04ee 0x00 0
						0 0x04ef 0x00 0
						0 0x04f0 0x80 0
						0 0x04f1 0x07 0
						0 0x04f2 0xa0 0
						0 0x04f3 0x00 0
						0 0x04f4 0x38 0
						0 0x04f5 0x04 0
						0 0x04f6 0x08 0
						0 0x04f7 0x24 0
						0 0x04f8 0x01 0
						0 0x05d8 0x00 0
						0 0x05d9 0x0a 0
						0 0x05da 0x23 0
						0 0x05db 0x40 0
						0 0x05dc 0x10 0
						0 0x05dd 0x00 0
						0 0x05de 0x40 0
						0 0x05df 0x51 0
						0 0x05e0 0x00 0
						0 0x05e1 0x00 0
						0 0x05e2 0x00 0
						0 0x05e3 0x00 0
						0 0x05e4 0x28 0
						0 0x05e5 0x00 0
						0 0x05e6 0xf8 0
						0 0x05e7 0x07 0
						0 0x05e8 0x5c 0
						0 0x05e9 0x04 0
						0 0x05ea 0x00 0
						0 0x05eb 0x00 0
						0 0x05ec 0x00 0
						0 0x05ed 0x78 0
						0 0x05ee 0x00 0
						0 0x05ef 0x00 0
						0 0x05f0 0x80 0
						0 0x05f1 0x07 0
						0 0x05f2 0xa0 0
						0 0x05f3 0x00 0
						0 0x05f4 0x38 0
						0 0x05f5 0x04 0
						0 0x05f6 0x08 0
						0 0x05f7 0x24 0
						0 0x05f8 0x01 0
						0 0x05cd 0x14 0
						0 0x6420 0x10 0
						0 0x7019 0x00 0
						0 0x7a14 0x00 0
						0 0x7000 0x00 0
						0 0x7054 0x01 1000
						0 0x7074 0x14 0
						0 0x7070 0x04 0
						0 0x04d0 0x0a 0
						0 0x05d0 0x0a 0
						0 0x6064 0x0f 0
						0 0x6065 0x0f 0
						0 0x6164 0x0f 0
						0 0x6165 0x0f 0
						0 0x6264 0x0f 0
						0 0x6265 0x0f 0
						0 0x6364 0x0f 0
						0 0x6365 0x0f 0
						0 0x7000 0x01 1000
						0 0x7a18 0x05 0
						0 0x7a28 0xff 0
						0 0x7a2a 0xff 0
						0 0x7a24 0xff 0
						0 0x7a27 0x0f 0
						0 0x7a14 0x01 0
						0 0x6421 0x01 0
						0 0x6420 0x11 100
						0 0x6420 0x10 100
						0 0x6420 0x11 0
					>;
					serdes-superframe-touch-init-cmd = <
					>;
					bl-i2c-addr = <0x1a>;
					bl-on-cmd = <
						0x83 0x50 0x00 0x01 0x00 0x00 0x00 0x00 0x00 0x00 0xd4
					>;
					bl-off-cmd = <
						0x83 0x00 0x00 0x02 0x00 0x00 0x00 0x00 0x00 0x00 0x85
					>;
				};
				asymmetric-multi-view-setting{
				};
			};

			max96851-dual-link-setting{
			};

			max96851-dp-mst-setting{
			};
		};

		BYD-1080{
			max96851-signal-settting{
				ser-init-cmd = <
					0 0x0100 0x61 0
					0 0x7000 0x00 0
					0 0x7019 0x00 0
					0 0x70a0 0x04 0
					0 0x7074 0x14 0
					0 0x7070 0x04 0
					0 0x7000 0x01 200
				>;
				des-i2c-addr = <0x4a>;
				des-init-cmd = <
					1 0x0215 0x10 0
					1 0x0227 0x10 0
					1 0x020f 0x10 0
					1 0x021b 0x10 0
					1 0x020c 0x10 0
					1 0x0209 0x10 0
					1 0x0212 0x10 0
					1 0x005b 0x31 0
					1 0x0063 0x31 0
					1 0x006b 0x31 0
					1 0x0073 0x31 0
					1 0x007b 0x31 0
					1 0x008b 0x31 0
					1 0x00a3 0x31 0
					1 0x00ab 0x31 0
					1 0x0140 0x20 0
					1 0x0002 0x43 0
					1 0x01d2 0x22 0
					1 0x01d4 0x44 0
					1 0x0010 0x11 0
					1 0x01ce 0x5e 0
					1 0x01c8 0x38 0
					1 0x01c9 0x39 0
					1 0x01ca 0x3a 0
					1 0x0002 0x03 0
					1 0x0d00 0xf4 0
					1 0x0002 0x43 0
					1 0x0d00 0xf5 0
					1 0x01c8 0x18 0
					1 0x01c9 0x19 0
					1 0x01ca 0x1a 0
				>;
				touch-init-cmd =<
					1 0x0206 0x03 0
					1 0x0207 0xab 0
					1 0x0208 0x4b 0
					0 0x0258 0x00 0
					0 0x0259 0xab 0
					0 0x025a 0x4b 0
					0 0x025b 0x22 0
				>;
				bl-i2c-addr = <0x1a>;
				bl-on-cmd = <
					0x83 0x50 0x00 0x01 0x00 0x00 0x00 0x00 0x00 0x00 0x00
				>;
				bl-off-cmd = <
					0x83 0x00 0x00 0x02 0x00 0x00 0x00 0x00 0x00 0x00 0x85
				>;
			};

			max96851-superframe-setting{
				asymmetric-multi-view = <0>;
				symmetric-multi-view-setting{
					des-i2c-addr = <0x4a>;
					serdes-init-linka-cmd = <
					>;
					des-linka-i2c-addr = <0x4a>;
					des-linka-bl-i2c-addr = <0x1b>;
					des-linka-init-cmd = <
					>;
					des-linkb-i2c-addr = <0x48>;
					des-linkb-bl-i2c-addr = <0x1c>;
					serdes-init-linkb-cmd = <
					>;
					des-linkb-init-cmd = <
					>;
					ser-superframe-init-cmd = <
					>;
					serdes-superframe-touch-init-cmd = <
					>;
					bl-i2c-addr = <0x1a>;
					bl-on-cmd = <
						0x83 0x50 0x00 0x01 0x00 0x00 0x00 0x00 0x00 0x00 0x00
					>;
					bl-off-cmd = <
						0x83 0x00 0x00 0x02 0x00 0x00 0x00 0x00 0x00 0x00 0x85
					>;
				};
				asymmetric-multi-view-setting{
				};
			};

			max96851-dual-link-setting{
			};

			max96851-dp-mst-setting{
			};
		};

		BYD-720{
			max96851-signal-settting{
				ser-init-cmd = <
				>;
				des-i2c-addr = <0x4a>;
				des-init-cmd = <
				>;
				touch-init-cmd =<
				>;
				bl-i2c-addr = <0x1a>;
				bl-on-cmd = <
					0x83 0x50 0x00 0x01 0x00 0x00 0x00 0x00 0x00 0x00 0xd4
				>;
				bl-off-cmd = <
					0x83 0x00 0x00 0x02 0x00 0x00 0x00 0x00 0x00 0x00 0x85
				>;
			};
			max96851-superframe-setting{
				asymmetric-multi-view = <0>;
				symmetric-multi-view-setting{
					des-i2c-addr = <0x4c>;
					serdes-init-linka-cmd = <
					>;
					des-linka-i2c-addr = <0x4a>;
					des-linka-bl-i2c-addr = <0x1b>;
					des-linka-init-cmd = <
					>;
					des-linkb-i2c-addr = <0x48>;
					des-linkb-bl-i2c-addr = <0x1c>;
					serdes-init-linkb-cmd = <
					>;
					des-linkb-init-cmd = <
					>;
					ser-superframe-init-cmd = <
					>;
					serdes-superframe-touch-init-cmd = <
					>;
					bl-i2c-addr = <0x1a>;
					bl-on-cmd = <
						0x83 0x50 0x00 0x01 0x00 0x00 0x00 0x00 0x00 0x00 0xd4
					>;
					bl-off-cmd = <
						0x83 0x00 0x00 0x02 0x00 0x00 0x00 0x00 0x00 0x00 0x85
					>;
				};
				asymmetric-multi-view-setting{
				};
			};
			max96851-dual-link-setting{
			};
			max96851-dp-mst-setting{
			};
		};

		ports {
			port@0 {
				reg = <0>;
				serdes_in: endpoint {
					remote-endpoint = <&edptx_out>;
				};
			};

			port@1 {
				reg = <1>;
				serdes_out: endpoint {
					remote-endpoint = <&panel_edp_in>;
				};
			};
		};
	};
};

&max96789 {
	setting_compatible: compatible-node {
		comp-cmd = <
			0x01 0x1a 0x0b 0x83 0x50 0x00 0x01 0x00 0x00 0x00 0x00 0x00 0x00 0xd4
			0x00 0x1a 0x0b
		>;
		comp-exp {
			comp-setting =  <0xf0 0x10 &setting_bt>,
							<0xff 0xff &setting_hy>,
							<0xff 0x00 &setting_yw_1080p>;
		};
	};

	setting_yw_1080p: setting@0 {
		ser-dual-link = <0>;

		ser-init-cmd = <
			0x0002 0x03 0x0
			0x1404 0x29 0x0
			0x1504 0x29 0x0
			0x14a4 0xc8 0x0
			0x15a4 0xc8 0x0
			0x140a 0x00 0x0
			0x150a 0x00 0x0
			0x140b 0x00 0x0
			0x150b 0x00 0x0
			0x0330 0x04 0x0
			0x0331 0x33 0x0
			0x0333 0xe4 0x0
			0x0308 0x7c 0x0
			0x0053 0x10 0x0
			0x005b 0x12 0x0
			0x0140 0x20 0x0
			0x0002 0x53 0x0
			0x0010 0x11 0x64
			0x02dc 0x04 0x0
			0x02dd 0x1e 0x0
			0x02de 0x5e 0x0
		>;
		desdef {
			des-i2c-addr = <0x4a>;
			des-init-cmd = <
				0x0215 0x10 0x0
				0x0227 0x10 0x0
				0x020f 0x10 0x0
				0x021b 0x10 0x0
				0x020c 0x10 0x0
				0x0209 0x10 0x0
				0x0212 0x10 0x0
				0x005b 0x31 0x0
				0x0063 0x31 0x0
				0x006b 0x31 0x0
				0x0073 0x31 0x0
				0x007b 0x31 0x0
				0x008b 0x31 0x0
				0x00a3 0x31 0x0
				0x00ab 0x31 0x0
				0x0140 0x20 0x0
				0x0002 0x43 0x0
				0x01d2 0x22 0x0
				0x01d4 0x44 0x0
				0x0010 0x11 0x0
				0x01ce 0x5e 0x0
				0x01c8 0x38 0x0
				0x01c9 0x39 0x0
				0x01ca 0x3a 0x0
				0x0002 0x03 0x0
				0x0d00 0xf4 0x0
				0x0002 0x43 0x0
				0x0d00 0xf5 0x0
				0x01c8 0x18 0x0
				0x01c9 0x19 0x0
				0x01ca 0x1a 0x0
				0x0206 0x0b 0x0
				0x0207 0x7e 0x0
				0x0208 0x5e 0x0
			>;
			panel-mode-setting {
				panel-mode-width = <1920>;
				panel-mode-height = <1080>;
				panel-mode-hfp = <112>;
				panel-mode-hsa = <24>;
				panel-mode-hbp = <32>;
				panel-mode-vfp = <16>;
				panel-mode-vsa = <3>;
				panel-mode-vbp = <24>;
				panel-mode-vrefresh = <60>;
				panel-mode-pll = <478>;
				panel-mode-lppf = <1>;
				panel-mode-width-mm = <129>;
				panel-mode-height-mm = <64>;
			};
		};
	};
	setting_bt: setting@1 {
		ser-super-frame = <0>;

		ser-init-cmd = <
			0x0001 0x08 0x00
			0x0203 0x00 0x00
			0x1404 0x29 0x00
			0x1504 0x29 0x00
			0x14a4 0xc8 0x00
			0x15a4 0xc8 0x00
			0x140a 0x00 0x00
			0x150a 0x00 0x00
			0x140b 0x00 0x00
			0x150b 0x00 0x00
			0x0330 0x04 0x00
			0x0331 0x33 0x00
			0x0333 0xe4 0x00
			0x0308 0x7c 0x00
			0x0053 0x10 0x00
			0x005b 0x12 0x14
			0x0140 0x20 0x00
			0x0002 0x53 0x05
			0x0010 0x31 0xc8
		>;
		desdef {
			des-i2c-addr = <0x4c>;
			bl-i2c-addr = <0x1a>;
			des-init-cmd = <
				0x01ce 0x5e 2
			>;
			bl-on-cmd = <
				0x83 0x50 0x00 0x01 0x00 0x00 0x00 0x00 0x00 0x00 0xd4
			>;
			bl-off-cmd = <
				0x83 0x00 0x00 0x02 0x00 0x00 0x00 0x00 0x00 0x00 0x85
			>;
			panel-mode-setting {
				panel-mode-width = <1920>;
				panel-mode-height = <1080>;
				panel-mode-hfp = <40>;
				panel-mode-hsa = <42>;
				panel-mode-hbp = <78>;
				panel-mode-vfp = <24>;
				panel-mode-vsa = <3>;
				panel-mode-vbp = <9>;
				panel-mode-vrefresh = <60>;
				panel-mode-lppf = <1>;
				panel-mode-width-mm = <129>;
				panel-mode-height-mm = <64>;
			};
		};
	};
	setting_hy: setting@2 {
		ser-super-frame = <0>;

		ser-init-cmd = <
			0x0001 0x08 0x00
			0x0203 0x00 0x00
			0x1404 0x29 0x00
			0x1504 0x29 0x00
			0x14a4 0xc8 0x00
			0x15a4 0xc8 0x00
			0x140a 0x00 0x00
			0x150a 0x00 0x00
			0x140b 0x00 0x00
			0x150b 0x00 0x00
			0x0330 0x04 0x00
			0x0331 0x33 0x00
			0x0333 0xe4 0x00
			0x0308 0x7c 0x00
			0x0053 0x10 0x00
			0x005b 0x12 0x14
			0x0140 0x20 0x00
			0x0002 0x53 0x05
			0x0010 0x31 0xc8
		>;
		desdef {
			des-i2c-addr = <0x4c>;
			bl-i2c-addr = <0x1a>;
			des-init-cmd = <
				0x01ce 0x4e 2
			>;
			bl-on-cmd = <
				0x83 0x50 0x00 0x01 0x00 0x00 0x00 0x00 0x00 0x00 0xd4
			>;
			bl-off-cmd = <
				0x83 0x00 0x00 0x02 0x00 0x00 0x00 0x00 0x00 0x00 0x85
			>;
			panel-mode-setting {
				panel-mode-width = <1920>;
				panel-mode-height = <1080>;
				panel-mode-hfp = <40>;
				panel-mode-hsa = <42>;
				panel-mode-hbp = <78>;
				panel-mode-vfp = <24>;
				panel-mode-vsa = <3>;
				panel-mode-vbp = <9>;
				panel-mode-vrefresh = <60>;
				panel-mode-lppf = <1>;
				panel-mode-width-mm = <129>;
				panel-mode-height-mm = <64>;
			};
		};
	};
};

&mipi_tx_config0 {
	status = "disabled";
};

&mipi_tx_config1 {
	status = "disabled";
};

&mipi_tx_config2 {
	status = "disabled";
};

&panel_dp {
	status = "disabled";
	panel-name = "BYD-1080";
	panel-mode = "signal-setting";

	BoTai{
		signal-setting{
			width-mm = <129>;
			height-mm = <64>;
			panel-timing {
				clock-frequency = <139526400>;
				hactive = <1920>;
				vactive = <1080>;
				hsync-len = <40>;
				hfront-porch = <40>;
				hback-porch = <80>;
				vfront-porch = <24>;
				vback-porch = <10>;
				vsync-len = <2>;
			};
		};
		superframe-setting{
			width-mm = <129>;
			height-mm = <64>;
			panel-timing {
				clock-frequency = <278553600>;
				hactive = <3840>;
				vactive = <1080>;
				hsync-len = <80>;
				hfront-porch = <80>;
				hback-porch = <160>;
				vfront-porch = <24>;
				vback-porch = <10>;
				vsync-len = <2>;
			};
		};
	};

	HuaYang{
		signal-setting{
			width-mm = <129>;
			height-mm = <64>;
			panel-timing {
				clock-frequency = <139526400>;
				hactive = <1920>;
				vactive = <1080>;
				hsync-len = <40>;
				hfront-porch = <40>;
				hback-porch = <80>;
				vfront-porch = <24>;
				vback-porch = <10>;
				vsync-len = <2>;
			};
		};
		superframe-setting{
			width-mm = <129>;
			height-mm = <64>;
			panel-timing {
				clock-frequency = <278553600>;
				hactive = <3840>;
				vactive = <1080>;
				hsync-len = <80>;
				hfront-porch = <80>;
				hback-porch = <160>;
				vfront-porch = <24>;
				vback-porch = <10>;
				vsync-len = <2>;
			};
		};
	};

	BYD-1080{
		signal-setting{
			width-mm = <129>;
			height-mm = <64>;
			panel-timing {
				clock-frequency = <158709600>;
				hactive = <1920>;
				vactive = <1080>;
				hsync-len = <20>;
				hfront-porch = <14>;
				hback-porch = <20>;
				vfront-porch = <230>;
				vback-porch = <28>;
				vsync-len = <2>;
			};
		};
		superframe-setting{
			width-mm = <129>;
			height-mm = <64>;
			panel-timing {
				clock-frequency = <317419200>;
				hactive = <3840>;
				vactive = <1080>;
				hsync-len = <40>;
				hfront-porch = <28>;
				hback-porch = <40>;
				vfront-porch = <230>;
				vback-porch = <28>;
				vsync-len = <2>;
			};
		};
	};

	BYD-720{
		signal-setting{
			width-mm = <129>;
			height-mm = <64>;
			panel-timing {
				clock-frequency = <88135920>;
				hactive = <1920>;
				vactive = <720>;
				hsync-len = <16>;
				hfront-porch = <44>;
				hback-porch = <24>;
				vfront-porch = <7>;
				vback-porch = <4>;
				vsync-len = <2>;
			};
		};
		superframe-setting{
			width-mm = <129>;
			height-mm = <64>;
			panel-timing {
				clock-frequency = <265970880>;
				hactive = <3840>;
				vactive = <720>;
				hsync-len = <32>;
				hfront-porch = <88>;
				hback-porch = <48>;
				vfront-porch = <14>;
				vback-porch = <8>;
				vsync-len = <4>;
			};
		};
	};

	port {
		panel_dp_in: endpoint {
			remote-endpoint = <&dptx_out>;
		};
	};
};

&panel_edp {
	status = "disabled";
	width-mm = <344>;
	height-mm = <194>;
	panel-timing {
		clock-frequency = <148500000>;
		hactive = <1920>;
		vactive = <1080>;
		hsync-len = <44>;
		hfront-porch = <88>;
		hback-porch = <148>;
		vfront-porch = <4>;
		vback-porch = <36>;
		vsync-len = <5>;
	};

	port {
		panel_edp_in: endpoint {
			remote-endpoint = <&edptx_out>;
		};
	};
};
